# psoc6_01 register map
Vendor: Cypress Semiconductor; Series: psoc6_01; File version: 1.0
CPU: CM4 r0p1, little endian, MPU, FPU, VTOR, 3 interrupt priority bits
Registers are 32-bit, read-write, reset 0x0 unless marked. A register's access mark holds for its fields unless they carry their own. Offsets are from the block's base; [hi:lo] are bit positions; lines under a group give offsets from that group; 'fields as' and 'values as' point back to an identical list.

## USBFS0 (part 2 of 2) — USB Host and Device Controller
Base 0x403F0000
0x4000 USBHOST group — USB Host Controller
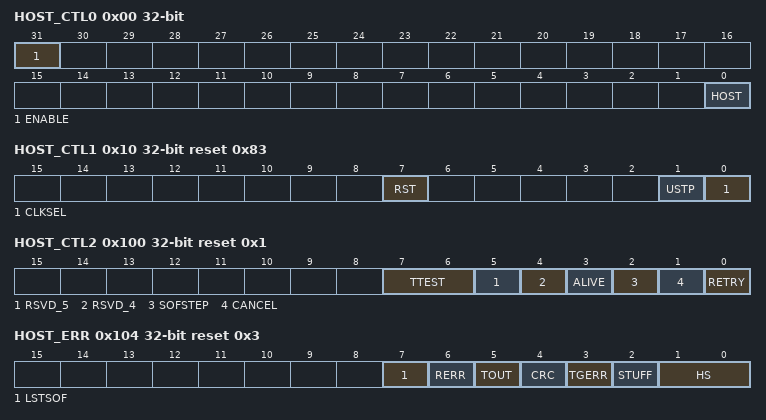
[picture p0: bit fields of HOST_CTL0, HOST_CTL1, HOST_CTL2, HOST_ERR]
  0x00 HOST_CTL0 — Host Control 0 Register.
    [31] ENABLE — This bit enables the operation of this IP. '0' : Disable USB Host '1' : Enable USB Host Note: - This bit doesn' affect the USB Device.
    [0] HOST — This bit selects an operating mode of this IP. '0' : USB Device '1' : USB Host Notes: - The operation mode does not transition to the required one immediately after it was changed using this bit. Read this bit to check that the operation mode has changed. - This bit is initialized if ENABLE bit of the Host Control 0 Register (HOST_CTL0) changes from '1' to '0'.. - Before changing from the USB Host to the USB Device, check that the following conditions are satisfied and also set the RST bit of the Host Control 1 Register (HOST_CTL1). to '1'. * The SOFBUSY bit of the Host Status Register (HOST_STATUS) is set to '0'. * The TKNEN bits of the Host Token Endpoint Register (HOST_TOKEN) is set to '000'. * The SUSP bit of the Host Status Register (HOST_STATUS) is set to '0'.
  0x10 HOST_CTL1 reset 0x83 — Host Control 1 Register.
    [7] RST — This bit resets this IP. '0' : Releases the reset for USB Host. '1' : Resets USB Host. Notes: - This bit is initialized if ENABLE bit of the Host Control 0 Register changes from '1' to '0'. - If this bit is set to '1', both the BFINI bits of the Host Endpoint 1 Control Register (HOST_EP1_CTL) and Host Endpoint 2 Control Register (HOST_EP2_CTL) are set to '1'.
    [1] USTP — This bit stops the clock for the USB Host operating unit. When this bit is '1', power consumption can be reduced by configuring this bit. '0' : Normal mode. '1' : Stops the clock for the USB Host operating unit. Notes: - If this bit is set to '1', the function of USB Host can't be used because internal clock is stopped. - This bit is initialized if ENABLE bit of the Host Control 0 Register (HOST_CTL0) changes from '1' to '0'.
    [0] CLKSEL — This bit selects the operating clock of USB Host. '0' : Low-speed clock '1' : Full-speed clock Notes: - This bit is initialized if ENABLE bit of the Host Control 0 Register (HOST_CTL0) changes from '1' to '0'. - This bit must always be set to '1' in the USB Device mode.
  0x100 HOST_CTL2 reset 0x1 — Host Control 2 Register.
    [7:6] TTEST — Timer Test. Set this bits to '00'.
    [5] RSVD_5
    [4] RSVD_4
    [3] ALIVE — This bit is used to specify the keep-alive function in the low-speed mode. If this bit it set to '1' while the CLKSEL bit of the Host Control 1 Register (HOST_CTL1) is '0', SE0 is output instead of SOF. This bit is effective when the CLKSEL bit of the Host Conrtol 1 Register (HOST_CTL1) is '0'. If the CLKSEL bit is '1', SOF is output regardless of the setting of the ALIVE bit. '0' : SOF output. '1' : SE0 output (Keep alive)
    [2] SOFSTEP — If this bit is set to '1', the SOF interrupt flag (INTR_USBHOST.SOFIRQ) is set to '1' each time SOF is sent. If this bit is set to '0', the set value of the Host SOF Interrupt Frame Compare Register (HOST_FCOMP) is compared with the low-order eight bits of the SOF frame number. If they match, the SOF interrupt flag (INTR_USBHOST.SOFIRQ) is set to '1'. '0' : An interrupt occurred due to the HOST_HFCOMP setting. '1' : An interrupt occurred. Notes: - If a SOF token (TKNEN='001') is sent by the setting of the Host Token Endpoint Register (HOST_TOKEN), the SOF interrupt flag (INTR_USBHOST.SOFIRQ) is not set to '1' regardless of the setting of this bit.
    [1] CANCEL — When this bit is set to '1', if the target token is written to the Host Token Endpoint Register (HOST_TOKEN) in the EOF area (specified in the Host EOF Setup Register), its sending is canceled. When this bit is set to '0', token sending is not canceled even if the target token is written to the register. The cancellation of token sending is detected by reading the TCAN bit of the Interrupt USB Host Register (INTR_USBHOST). '0' : Continues a token. '1' : Cancels a token.
    [0] RETRY — If this bit is set to '1', the target token is retried if a NAK or error* occurs. Retry processing is performed during the time that is specified in the Host Retry Timer Setup Register (HOST_RTIMER). * : HOST_ERR.RERR='1', HOST_ERR.TOUT='1', HOST_ERR.CRC='1', HOST_ERR.TGERR='1', HOST_ERR.STUFF='1' '0' : Doesn't retry token sending. '1' : Retries token sending Note: - This bit isn't initialized even if the RST bit of the Host Control 1 Register (HOST_CTL1) is set to '1'.
  0x104 HOST_ERR reset 0x3 — Host Error Status Register.
    [7] LSTSOF — If this bit is set to '1', it means that the SOF token can't be sent in the USB Host because other token is in process. When this bit is '0', it means that no lost SOF error is detected. If this bit is written with '1', it is set to '0'. However, if this bit is written with '0', its value is ignored. '0' : Sends SOF. '1' : SOF sending error. Note: - This bit is set to the initial value when the RST bit of the Host Control 1 Register (HOST_CTL1) is set to '1'.
    [6] RERR — When this bit is set to '1', it means that the received data exceeds the specified maximum number of packets in the USB Host. If a receive error is detected, bit5 (Timeout) of this register is also set to '1'. When this bit is '0', it means that no error occurs. If this bit is written with '1', it is set to '0'. However, if this bit is written with '0', its value is ignored. '0' : No receive error. '1' : Maximum packet receive error. - This bit is set to the initial value when the RST bit of the Host Control 1 Register (HOST_CTL1) is set to '1'.
    [5] TOUT — If this bit is set to '1', it means that no response is returned from the device within the specified time after a token has been sent in the USB Host. When this bit is '0', it means that no timeout is detected. When this bit is '0', it means that no error occurs. If this bit is written with '1', it is set to '0'. However, if this bit is written with '0', its value is ignored. '0' : No timeout. '1' : Timeout occurs. Note: - This bit is set to the initial value when the RST bit of the Host Control 1 Register (HOST_CTL1) is set to '1'.
    [4] CRC — If this bit is set to '1', it means that a CRC error is detected in the USB Host. When this bit is '0', it means that no CRC error is detected. If a CRC error is detected, bit5 (Timeout) of this register is also set to '1'. When this bit is '0', it means that no CRC error is detected. If this bit is written with '1', it is set to '0'. However, if this bit is written with '0', its value is ignored. '0' : No CRC error. '1' : CRC error occurs. Note: - This bit is set to the initial value when the RST bit of the Host Control 1 Register (HOST_CTL1) is set to '1'.
    [3] TGERR — If this bit is set to '1', it means that the data of this bit does not match the value of the received toggle data. When this bit is '0', it means that no toggle error is detected. If this bit is written with '1', it is set to '0'. However, if this bit is written with '0', its value is ignored. '0' : No toggle error. '1' : Toggle error occurs. Note: - This bit is set to the initial value when the RST bit of the Host Control 1 Register (HOST_CTL1) is set to '1'.
    [2] STUFF — If this bit is set to '1', it means that a bit stuffing error is detected. When this bit is '0', it means that no stuffing error is detected. If a stuffing error is detected, bit5 (Timeout) of this register is also set to '1'. If this bit is written with '1', it is set to '0'. However, if this bit is written with '0', its value is ignored. '0' : No stuffing error. '1' : Stuffing error occurs. Note: - This bit is set to the initial value when the RST bit of the Host Control 1 Register (HOST_CTL1) is set to '1'.
    [1:0] HS — These flags indicate the status of a handshake packet to be sent or received. These flags are set to 'NULL' when no handshake occurs due to an error or when a SOF token has been ended with the TKNEN bit of the Host Token Endpoint Register (HOST_TOKEN). These bits are updated when sending or receiving has been ended. HS bits change values '11' under the following condition. However, if HS bits are written except the following conditions, the values are ignored. - HS bits indicate values except '11' and write the value '11' to HS bits. Note: This bit is set to the initial value when the RST bit of the Host Control 1 Register (HOST_CTL1) is set to '1'.
      0=ACK (Acknowledge Packet); 1=NAK (Non-Acknowledge Packet); 2=STALL (Stall Packet); 3=NULL (Null Packet)
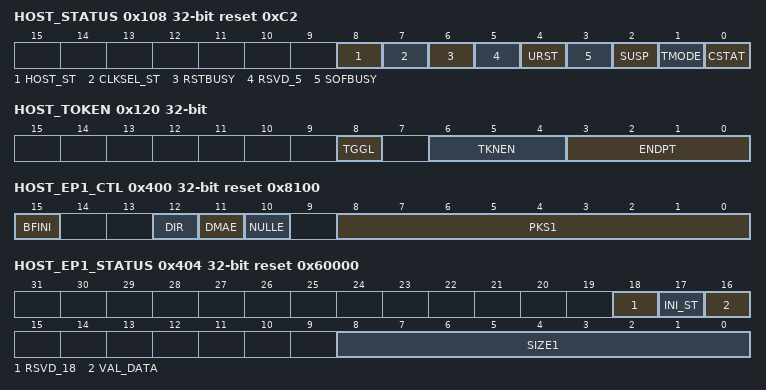
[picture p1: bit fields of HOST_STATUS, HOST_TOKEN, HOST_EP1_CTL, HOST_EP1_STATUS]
  0x108 HOST_STATUS reset 0xC2
    [8] HOST_ST ro — This bit shows whether it is USB Host mode. If the HOST bit of the Host Control Register (HOST_CTL0) is set to '1', this bit is set to '1'. '0' : USB Device '1' : USB Host Notes: - If this bit is different from the CLKSEL bit, The execution of the token must be waited until the match. - This bit takes time to be initialized by the RST bit of the Host Control 1 Resgiter (HOST_CTL1).
    [7] CLKSEL_ST ro — This bit shows whether it is full-speed or not. If the CLKSEL bit of the Host Control 1 Register (HOST_CTL1) is set to '1', this bit is set to '1'. '0' : Low speed '1' : Full speed Note: - If this bit is different from the CLKSEL bit, The execution of the token and bus reset must be waited until the match. - This bit takes time to be initialized by the RST bit of the Host Control 1 Resgiter (HOST_CTL1).
    [6] RSTBUSY ro — This bit shows that USB Host is being reset internally. If the RST bit of the Host Control 1 Register (HOST_CTL1) is set to '1', this bit is set to '1'. If the RST bit of Host Control 1 Register (HOST_CTL1) is set to '0', this bit is set to '0'. '0' : USB Host isn't being reset. '1' : USB Host is being reset. Notes: - If this bit is '1', the token must't be executed. - This bit isn't set to '0' or '1' immediately evne if the RST bit of Host Control 1 Register (HOST_CTL1) is set to '0' or '1'.
    [5] RSVD_5 ro
    [4] URST — When this bit is set to '1', the USB bus is reset. This bit continues set to '1' during USB bus resetting, and changes to '0' when USB bus resetting is ended. If this bit is set to '0', no processing is performed.
    [3] SOFBUSY — When a SOF token is sent using the Host Token Endpoint Register (HOST_TOKEN), this bit is set to '1', which means that the SOF timer is active. When this bit is '0', it means that the SOF timer is under suspension. To stop the active SOF timer, write '0' to this bit. However, if this bit is written with '1', its value is ignored. '0' : The SOF timer is stopped. '1' : The SOF timer is active. Notes: - This bit is set to the initial value when the RST bit of the Host Control 1 Register (HOST_CTL1) is set to '1'. - This bit takes time to be initialized by the RST bit of the Host Control 1 Resgiter (HOST_CTL1). - The SOF timer does not stop immediately after this bit has been set to '0' to stop the SOF timer. To check whether or not the SOF timer is stopped, read this bit.
    [2] SUSP — If this bit is set to '1', the USB Host is placed into the suspend state. If this bit is set to '0' while it is '1' or the USB bus is placed into the k-state mode, the suspend state is released, and the RWIRQ bit of the Interrupt USB Host Register (INTR_USBHOST) is set to '1'. Set to '1' : Suspend. Set '0' while this bit is '1' : Resume. Others : Holds the status. Notes: - This bit is set to the initial value when the RST bit of the Host Control 1 Register (HOST_CTL1) is set to '1'. - This bit takes time to be initialized by the RST bit of the Host Control 1 Resgiter (HOST_CTL1). - If this bit is set to '1', this bit must not be set to '1' until the RWIRQ bit of the Interrupt USB Host Register (INTR_USBHOST) is set to '1'. - Do not set this bit to '1' while the USB is active (during USB bus resetting, data transfer, or SOF timer running). - If the value of this bit is changed, it is not immediately reflected on the state of the USB bus. To check whether or not the state is updated, read this bit.
    [1] TMODE ro — If this bit is '1', it means that the device is connected in the full-speed mode. When this bit is '0', it means that the device is connected in the low-speed mode. This bit is valid when the CSTAT bit of the Host Status Register (HOST_STATUS) is '1'. '0' : Low-speed. '1' : Full-speed. Notes: - This bit is initialized if the RST bit of the Host Control 1 Register (HOST_CTL1) is set to '1'. - This bit takes time to be initialized by the RST bit of the Host Control 1 Resgiter (HOST_CTL1).
    [0] CSTAT ro — When this bit is '1', it means that the device is connected. When this bit is '0', it means that the device is disconnected. '0' : Device is disconnected. '1' : Device is connected. Notes: - This bit is initialized if the RST bit of the Host Control 1 Register (Host_CTL1) is set to '1'. - This bit takes time to be initialized by the RST bit of the Host Control 1 Resgiter (HOST_CTL1).
  0x10C HOST_FCOMP — Host SOF Interrupt Frame Compare Register
    [7:0] FRAMECOMP — These bits are used to specify the data to be compared with the low-order eight bits of a frame number when sending a SOF token. If the SOFSTEP bit of Host Control 2 Register (HOST_CTL2) is '0', the frame number of SOF is compared with the value of this register when sending a SOF token. If they match, the SOFIRQ bit of the Interrupt USB Host Register (INTR_USBHOST) is set to '1'. The setting of this register is invalid when the SOFSTEP bit of Host Control 2 Register (HOST_CTL2) is '1'. Note: - This bit is not initialized even if the RST bit of the Host Control 1 Register (HOST_CTL1) is set to '1'.
  0x110 HOST_RTIMER — Host Retry Timer Setup Register
    [17:0] RTIMER — These bits are used to specify the retry time in this register. The retry timer is activated when token sending starts while the RETRY bit of Host Control 2 Register (HOST_CTL2) is '1'. The retry time is then decremented by one when a 1-bit transfer clock (12 MHz in the full-speed mode) is output. When the retry timer reaches 0, the target token is sent, and processing is ended. If a token retry occurs in the EOF area, the retry timer is stopped until SOF sending is ended. After SOF sending has been completed, the retry timer restarts with the value that is set when the timer stopped.
  0x114 HOST_ADDR — Host Address Register
    [6:0] ADDRESS — These bits are used to specify a token address. Note: - This bit is not initialized even if the RST bit of the Host Control 1 Register (HOST_CTL1) is set to '1'.
  0x118 HOST_EOF — Host EOF Setup Register
    [13:0] EOF — These bits are used to specify the time to disable token sending before transferring SOF. Specify the time with a margin, which is longer than the one-packet length. The time unit is the 1-bit transfer time. Setting example: MAXPKT = 64 bytes, full-speed mode (Token_length + packet_length + header + CRC)*7/6 + Turn_around_time =(34 bit + 546 bit)*7/6 + 36 bit = 712.7 bit Therefore, set 0x2C9. Note: - This bit is not initialized even if the RST bit of the Host Control 1 Register (HOST_CTL1) is set to '1'.
  0x11C HOST_FRAME — Host Frame Setup Register
    [10:0] FRAME — These bits are used to specify a frame number of SOF. Notes: - This bit isn't initialized even if the RST bit of the Host Control 1 Register (HOST_CTL1) is set to '1'. - Specify a frame number in this register before setting SOF in the TKNEN bit of the Host Token Endpoint Register (HOST_TOKEN). - This register cannot be written while the SOFBUSY bit of the Host Status Register (HOST_STATUS) is '1' and a SOF token is in process.
  0x120 HOST_TOKEN — Host Token Endpoint Register
    [8] TGGL — This bit is used to set toggle data. Toggle data is sent depending on the setting of this bit. When receiving toggle data, received toggle data is compared with the toggle data of this bit to verify whether or not an error occurs. '0' : DATA0 '1' : DATA1 Notes: - This bit isn't initialized even if the RST bit of the Host Control 1 Register (HOST_CTL1) is set to '1'. - Set this bit when the TKNEN bit of the Host Token Endpoint Register (HOST_TOKEN) is '000'.
    [6:4] TKNEN — These bits send a token according to the settings. After operation has been ended, the TKNEN bit is set to '000', and the CMPIRQ bit of the Interrupt USB Host Register (INTR_USBHOST) is set to '1'. The settings of the TGGL and ENDPT bits are ignored when sending a SOF token. Notes: - This bit is set to the initial value when the RST bit of the Host Control 1 Register (HOST_CTL1) is set to '1'. - The PRE packet isn't supported. - Do not set '100' to the TKNEN bit when the SOFBUSY bit of the Host Status Register (HOST_STATUS) is '1' - Change the USB to the USB Host before writing data to this bit. - When issuing a token again after the token interrupt flag (CMPIRQ) has been set to '1', wait for 3 cycles or more after a USB transfer clock (12 MHz in the full-speed mode, 1.5 MHz in the low-speed mode) was output, then write data to this bit. - Read the value of TKNEN bit if a new value is written in it .Continue writing in this bit until a retrieved value equals a new value written in. During this checking process, it is needed to prevent any interrupt. - Take the following steps when CMPIRQ bit of Interrupt USB Host Register (INTR_USBHOST) is set to '1' by finishing IN token or Isochronous IN token. 1. Read HS bit of Host Error Status Register (HOST_ERR), then set CMPIRQ bit to '0'. 2. Set EPn bit of Host DMA Enable Register (HOST_DMA_ENBL) (n=1 or 2) to '1' if HS bit of Host Error Status Register (HOST_ERR) is equal to '00' and wait until EPn bit of Host DMA Data Request Register (HOST_DMA_DREQ) changes to '1'. Finish the IN token processing if HS bit is not equal to '00'. 3. Read the received data if EPn bit of Host DMA Data Requet (HOST_DMA_DREQ) (n=1 or 2) changes to '1'.
      0=NONE (Sends no data.); 1=SETUP (Sends SETUP token.); 2=IN (Sends IN token.); 3=OUT (Sends OUT token.); 4=SOF (Sends SOF token.); 5=ISO_IN (Sends Isochronous IN.); 6=ISO_OUT (Sends Isochronous OUT.); 7=RSV (N/A)
    [3:0] ENDPT — These bits are used to specify an endpoint to send or receive data to or from the device. Note: - This bit isn't initialized even if the RST bit of the Host Control 1 Register (HOST_CTL1) is set to '1'.
  0x400 HOST_EP1_CTL reset 0x8100 — Host Endpoint 1 Control Register
    [15] BFINI — This bit initializes the send/receive buffer of transfer data. The BFINI bit is also automatically set by setting the RST bit of the HOST Control 1 Register (HOST_CTL1). If the RST bit was used for resetting, therefore, set the RST bit to '0' before clearing the BFINI bit. '0' : Clears the initialization. '1' : Initializes the send/receive buffer Note : - The EP1 buffer has a double-buffer configuration. The BFINI bit initialization initializes the double buffers concurrently and also initializes the EP1DRQ and EP1SPK bits.
    [12] DIR — This bit specifies the transfer direction the Endpoint support. '0' : IN Endpoint. '1' : OUT Endpoint Note: - This bit must be changed when INI_ST bit of the Host Endpoint 1 Status Register (HOST_EP1_STATUS) is '1'.
    [11] DMAE — This bit sets a mode that uses DMA for writing or reading transfer data to/from send/receive buffer, and automatically transfers the send/receive data synchronized with an data request in the IN or OUT direction. Until the data size set in the DMA is reached, the data is transferred. '0' : Releases the automatic buffer transfer mode. '1' : Sets the automatic buffer transfer mode. Note : - The CPU must not access the send/receive buffer while the DMAE bit is set to '1'. For data transfer in the IN direction, set the DMA transfer size to the multiples of that set in PKS bits of the Host EP1 Control Register (HOST_EP1_CTL) and Host EP2 Control Register (HOST_EP2_CTR).
    [10] NULLE — When a data transfer request in OUT the direction is transmitted while automatic buffer transfer mode is set (DMAE = 1), this bit sets a mode that transfers 0-byte data automatically upon the detection of the last packet transfer. '0' : Releases the NULL automatic transfer mode. '1' : Sets the NULL automatic transfer mode. Note : - For data transfer in the IN direction or when automatic buffer transfer mode is not set, the NULL bit configuration does not affect communication.
    [8:0] PKS1 — This bit specifies the maximum size transferred by one packet. The configurable range is from 0x001 to 0x100. - If automatic buffer transfer mode (DMEA='1') is used, this Endpoint must not set from 0 to 2.
  0x404 HOST_EP1_STATUS ro reset 0x60000 (reset mask 0x70000) — Host Endpoint 1 Status Register
    [18] RSVD_18
    [17] INI_ST — This bit shows that EP1 is initialized. If the init bit of the Host Endpoint 1 Control Register (HOST_EP1_CTL) is set to '1' and EP1 is initialized, this bit is to '1'. '0' : Release of the initialization '1' : Initialization Note: - This bit isn't set to '0' or '1' immediately evne if BFINI bit of the Host Endpoint 1 Control Register (HOST_EP1_CTL) is set to '0' or '1'.
    [16] VAL_DATA — This bit shows that there is valid data in the EP1 buffer. '0' : Invalid data in the buffer '1' : Valid data in the buffer
    [8:0] SIZE1 — These bits indicate the number of data bytes written to the receive buffer when IN packet transfer of EP1 has finished. The indication range is from 0x000 to 0x100. Note : - These bits are set to the data size transferred in the IN direction and written to the buffer. Therefore, a value read during transfer in the OUT direction has no effect.
  0x408 HOST_EP1_RW1_DR — Host Endpoint 1 Data 1-Byte Register
    [7:0] BFDT8 — Data Register for EP1. The 1-Byte data is valid.
  0x40C HOST_EP1_RW2_DR — Host Endpoint 1 Data 2-Byte Register
    [15:0] BFDT16 — Data Register for EP1. The 2-Byte data is valid.
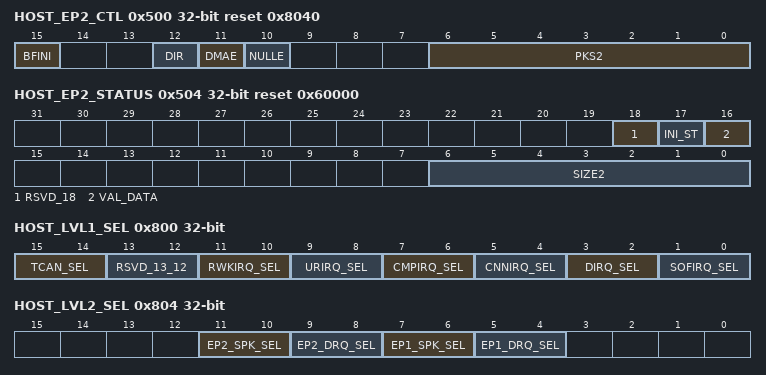
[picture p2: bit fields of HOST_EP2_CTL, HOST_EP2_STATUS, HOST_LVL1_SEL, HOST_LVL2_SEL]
  0x500 HOST_EP2_CTL reset 0x8040 — Host Endpoint 2 Control Register
    [15] BFINI — This bit initializes the send/receive buffer of transfer data. The BFINI bit is also automatically set by setting the RST bit of the HOST Control 1 Register (HOST_CTL1). If the RST bit was used for resetting, therefore, set the RST bit to '0' before clearing the BFINI bit. '0' : Clears the initialization. '1' : Initializes the send/receive buffer Note : - The EP2 buffer has a double-buffer configuration. The BFINI bit initialization initializes the double buffers concurrently and also initializes the EP2DRQ and EP2SPK bits.
    [12] DIR — This bit specifies the transfer direction the Endpoint support. '0' : IN Endpoint. '1' : OUT Endpoint Note: - This bit must be changed when INI_ST bit of the Host Endpoint 2 Status Register (HOST_EP2_STATUS) is '1'.
    [11] DMAE — This bit sets a mode that uses DMA for writing or reading transfer data to/from send/receive buffer, and automatically transfers the send/receive data synchronized with an data request in the IN or OUT direction. Until the data size set in the DMA is reached, the data is transferred. '0' : Releases the automatic buffer transfer mode. '1' : Sets the automatic buffer transfer mode. Note : - The CPU must not access the send/receive buffer while the DMAE bit is set to '1'. For data transfer in the IN direction, set the DMA transfer size to the multiples of that set in PKS bits of the Host EP1 Control Register (HOST_EP1_CTL) and Host EP2 Control Register (HOST_EP2_CTR).
    [10] NULLE — When a data transfer request in OUT the direction is transmitted while automatic buffer transfer mode is set (DMAE = 1), this bit sets a mode that transfers 0-byte data automatically upon the detection of the last packet transfer. '0' : Releases the NULL automatic transfer mode. '1' : Sets the NULL automatic transfer mode. Note : - For data transfer in the IN direction or when automatic buffer transfer mode is not set, the NULL bit configuration does not affect communication.
    [6:0] PKS2 — This bit specifies the maximum size transferred by one packet. The configurable range is from 0x001 to 0x40. - If automatic buffer transfer mode (DMEA='1') is used, this Endpoint must not set from 0 to 2.
  0x504 HOST_EP2_STATUS ro reset 0x60000 (reset mask 0x70000) — Host Endpoint 2 Status Register
    [18] RSVD_18
    [17] INI_ST — This bit shows that EP2 is initialized. If the BFINI bit of the Host Endpoint 2 Control Register (HOST_EP2_CTL) is set to '1' and EP2 is initialized, this bit is to '1'. '0' : Release of the initialization '1' : Initialization Note: - This bit isn't set to '0' or '1' immediately evne if BFINI bit of the Host Endpoint 2 Control Register (HOST_EP2_CTL) is set to '0' or '1'.
    [16] VAL_DATA — This bit shows that there is valid data in the EP2 buffer. '0' : Invalid data in the buffer '1' : Valid data in the buffer
    [6:0] SIZE2 — These bits indicate the number of data bytes written to the receive buffer when IN packet transfer of EP2 has finished. The indication range is from 0x000 to 0x40. Note : - These bits are set to the data size transferred in the IN direction and written to the buffer. Therefore, a value read during transfer in the OUT direction has no effect.
  0x508 HOST_EP2_RW1_DR — Host Endpoint 2 Data 1-Byte Register
    [7:0] BFDT8 — Data Register for EP2. The 1-Byte data is valid.
  0x50C HOST_EP2_RW2_DR — Host Endpoint 2 Data 2-Byte Register
    [15:0] BFDT16 — Data Register for EP2. The 2-Byte data is valid.
  0x800 HOST_LVL1_SEL — Host Interrupt Level 1 Selection Register
    [15:14] TCAN_SEL — These bits assign TCAN interrupt flag to any interrupt signals.
    [13:12] RSVD_13_12
    [11:10] RWKIRQ_SEL — These bits assign RWKIRQ interrupt flag to any interrupt signals.
    [9:8] URIRQ_SEL — These bits assign URIRQ interrupt flag to any interrupt signals.
    [7:6] CMPIRQ_SEL — These bits assign URIRQ interrupt flag to any interrupt signals.
    [5:4] CNNIRQ_SEL — These bits assign CNNIRQ interrupt flag to any interrupt signals.
    [3:2] DIRQ_SEL — These bits assign DIRQ interrupt flag to any interrupt signals.
    [1:0] SOFIRQ_SEL — These bits assign SOFIRQ interrupt flag to any interrupt signals.
      0=HI (High priority interrupt); 1=MED (Medium priority interrupt); 2=LO (Low priority interrupt); 3=RSVD (illegal)
  0x804 HOST_LVL2_SEL — Host Interrupt Level 2 Selection Register
    [11:10] EP2_SPK_SEL — These bits assign EP2_SPK interrupt flag to any interrupt signals.
    [9:8] EP2_DRQ_SEL — These bits assign EP2_DRQ interrupt flag to any interrupt signals.
    [7:6] EP1_SPK_SEL — These bits assign EP1_SPK interrupt flag to any interrupt signals.
    [5:4] EP1_DRQ_SEL — These bits assign EP1_DRQ interrupt flag to any interrupt signals.
      values as USBHOST.HOST_LVL1_SEL.SOFIRQ_SEL
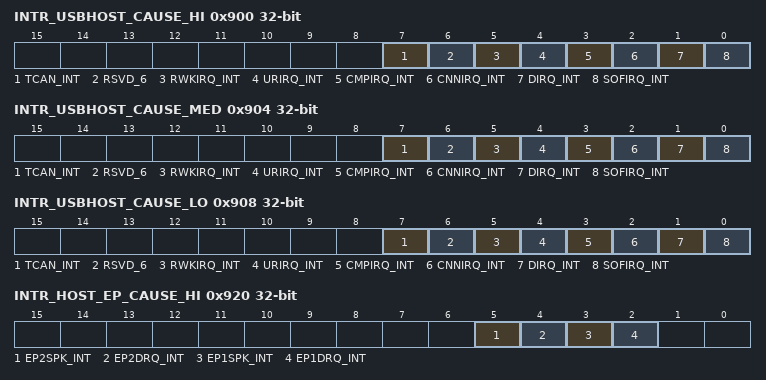
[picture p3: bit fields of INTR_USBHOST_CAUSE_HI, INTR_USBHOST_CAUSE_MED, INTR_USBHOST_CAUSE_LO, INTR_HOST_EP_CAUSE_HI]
  0x900 INTR_USBHOST_CAUSE_HI ro — Interrupt USB Host Cause High Register
    [7] TCAN_INT — TCAN interrupt
    [6] RSVD_6
    [5] RWKIRQ_INT — RWKIRQ interrupt
    [4] URIRQ_INT — URIRQ interrupt
    [3] CMPIRQ_INT — CMPIRQ interrupt
    [2] CNNIRQ_INT — CNNIRQ interrupt
    [1] DIRQ_INT — DIRQ interrupt
    [0] SOFIRQ_INT — SOFIRQ interrupt
  0x904 INTR_USBHOST_CAUSE_MED ro — Interrupt USB Host Cause Medium Register
    fields as USBHOST.INTR_USBHOST_CAUSE_HI
  0x908 INTR_USBHOST_CAUSE_LO ro — Interrupt USB Host Cause Low Register
    fields as USBHOST.INTR_USBHOST_CAUSE_HI
  0x920 INTR_HOST_EP_CAUSE_HI ro — Interrupt USB Host Endpoint Cause High Register
    [5] EP2SPK_INT — EP2SPK interrupt
    [4] EP2DRQ_INT — EP2DRQ interrupt
    [3] EP1SPK_INT — EP1SPK interrupt
    [2] EP1DRQ_INT — EP1DRQ interrupt
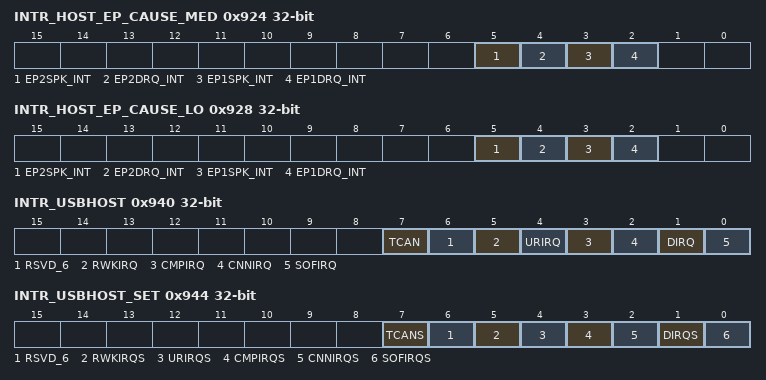
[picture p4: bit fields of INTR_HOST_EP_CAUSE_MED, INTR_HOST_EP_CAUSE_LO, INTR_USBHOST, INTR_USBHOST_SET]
  0x924 INTR_HOST_EP_CAUSE_MED ro — Interrupt USB Host Endpoint Cause Medium Register
    fields as USBHOST.INTR_HOST_EP_CAUSE_HI
  0x928 INTR_HOST_EP_CAUSE_LO ro — Interrupt USB Host Endpoint Cause Low Register
    fields as USBHOST.INTR_HOST_EP_CAUSE_HI
  0x940 INTR_USBHOST — Interrupt USB Host Register
    [7] TCAN — If this bit is set to '1', it means that token sending is canceled based on the setting of the CANCEL bit of Host Control 2 Register (HOST_CTL2). When this bit is '0', it means that token sending is not canceled. If this bit is written with '1', it is set to '0'. However, if this bit is written with '0', its value is ignored. '0' : Does not cancel token sending. '1' : Cancels token sending. Note : - This bit is set to the initial value when the RST bit of the Host Control 1 Register (HOST_CTL1) is set to '1'.
    [6] RSVD_6
    [5] RWKIRQ — If this bit is set to '1', it means that remote Wake-up is ended. When this bit is '0', it has no meaning. If this bit is written with '1', it is set to '0'. However, if this bit is written with '0', its value is ignored. '0' : Issues no interrupt request by restart. '1' : Issues an interrupt request by restart. Note : - This bit is set to the initial value when the RST bit of the Host Control 1 Register (HOST_CTL1) is set to '1'.
    [4] URIRQ — If this bit is set to '1', it means that USB bus resetting is ended. When this bit is '0', it has no meaning. If this bit is written with '1', it is set to '0'. However, if this bit is written with '0', its value is ignored. '0' : Issues no interrupt request by USB bus resetting. '1' : Issues an interrupt request by USB bus resetting. Note : - This bit is set to the initial value when the RST bit of the Host Control 1 Register (HOST_CTL1) is set to '1'.
    [3] CMPIRQ — If this bit is set to '1', it means that a token is completed. When this bit is '0', it has no meaning. If this bit is written with '1', it is set to '0'. However, if this bit is written with '0', its value is ignored. '0' : Issues no interrupt request by token completion. '1' : Issues an interrupt request by token completion. Note : - This bit is set to the initial value when the RST bit of the Host Control 1 Register (HOST_CTL1) is set to '1'. - This bit is not set to '1' even if the TCAN bit of the Interrupt USBHost Register (INTR_USBHOST) changes to '1'. - Take the following steps when this bit is set to '1' by finishing IN token or Isochronous IN token. 1. Read HS bit of Host Error Status Register (HOST_ERR), then set CMPIRQ bit to '0'. 2. Set EPn bit of Host DMA Enable Register (HOST_DMA_ENBL) (n=1 or 2) to '1' if HS bit of Host Error Status Register (HOST_ERR) is equal to '00' and wait until EPn bit of Host DMA Data Request Register (HOST_DMA_DREQ) changes to '1'. Finish the IN token processing if HS bit is not equal to '00'. 3. Read the received data if EPn bit of Host DMA Data Requet (HOST_DMA_DREQ) (n=1 or 2) changes to '1'.
    [2] CNNIRQ — If this bit is set to '1', it means that a device connection is detected. When this bit is '0', it has no meaning. If this bit is written with '1', it is set to '0'. However, if this bit is written with '0', its value is ignored. '0' : Issues no interrupt request by detecting a device connection. '1' : Issues an interrupt request by detecting a device connection. Note : - This bit is set to the initial value when the RST bit of the Host Control 1 Register (HOST_CTL1) is set to '1'.
    [1] DIRQ — If this bit is set to '1', it means that a device disconnection is detected. When this bit is '0', it has no meaning. If this bit is written with '1', it is set to '0'. However, if this bit is written with '0', its value is ignored. '0' : Issues no interrupt request by detecting a device disconnection. '1' : Issues an interrupt request by detecting a device disconnection. Note : - This bit is set to the initial value when the RST bit of the Host Control 1 Register (HOST_CTL1) is set to '1'.
    [0] SOFIRQ — If this bit is set to '1', it means that SOF token sending is started. When this bit is '0', it has no meaning. If this bit is written with '1', it is set to '0'. However, if this bit is written with '0', its value is ignored. '0' : Does not issue an interrupt request by starting a SOF token. '1' : Issues an interrupt request by starting a SOF token. Note : - This bit is set to the initial value when the RST bit of the Host Control 1 Register (HOST_CTL1) is set to '1'.
  0x944 INTR_USBHOST_SET — Interrupt USB Host Set Register
    [7] TCANS — This bit sets TCAN bit. If this bit is written to '1', TCAN is set to '1'. However, if this bit is written with '0', its value is ignored.
    [6] RSVD_6 — BCNFTEST interrupt. This bit is test bit
    [5] RWKIRQS — This bit sets RWKIRQ bit. If this bit is written to '1', RWKIRQ is set to '1'. However, if this bit is written with '0', its value is ignored.
    [4] URIRQS — This bit sets URIRQ bit. If this bit is written to '1', URIRQ is set to '1'. However, if this bit is written with '0', its value is ignored.
    [3] CMPIRQS — This bit sets CMPIRQ bit. If this bit is written to '1', CMPIRQ is set to '1'. However, if this bit is written with '0', its value is ignored.
    [2] CNNIRQS — This bit sets CNNIRQ bit. If this bit is written to '1', CNNIRQ is set to '1'. However, if this bit is written with '0', its value is ignored.
    [1] DIRQS — This bit sets DIRQ bit. If this bit is written to '1', DIRQ is set to '1'. However, if this bit is written with '0', its value is ignored.
    [0] SOFIRQS — This bit sets SOFIRQ bit. If this bit is written to '1', SOFIRQ is set to '1'. However, if this bit is written with '0', its value is ignored.
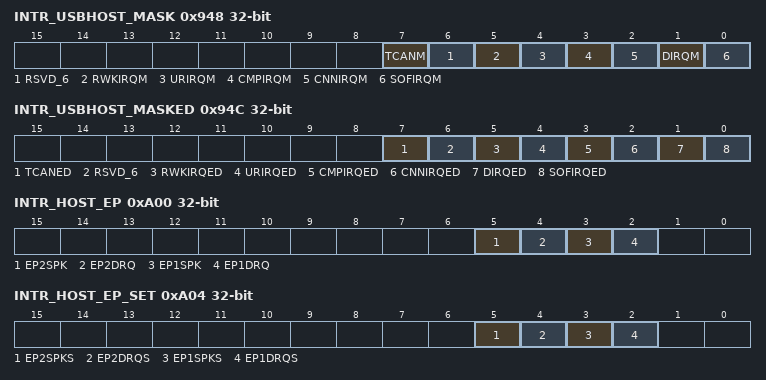
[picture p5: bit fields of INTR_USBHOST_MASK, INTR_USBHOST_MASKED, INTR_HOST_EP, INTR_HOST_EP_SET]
  0x948 INTR_USBHOST_MASK — Interrupt USB Host Mask Register
    [7] TCANM — This bit masks the interrupt by TCAN flag. '0' : Disables '1' : Enables
    [6] RSVD_6
    [5] RWKIRQM — This bit masks the interrupt by RWKIRQ flag. '0' : Disables '1' : Enables
    [4] URIRQM — This bit masks the interrupt by URIRQ flag. '0' : Disables '1' : Enables
    [3] CMPIRQM — This bit masks the interrupt by CMPIRQ flag. '0' : Disables '1' : Enables
    [2] CNNIRQM — This bit masks the interrupt by CNNIRQ flag. '0' : Disables '1' : Enables
    [1] DIRQM — This bit masks the interrupt by DIRQ flag. '0' : Disables '1' : Enables
    [0] SOFIRQM — This bit masks the interrupt by SOF flag. '0' : Disables '1' : Enables
  0x94C INTR_USBHOST_MASKED ro — Interrupt USB Host Masked Register
    [7] TCANED — This bit indicates the interrupt by TCAN flag. '0' : Doesn't request the interrupt by TCAN '1' : Request the interrupt by TCAN
    [6] RSVD_6
    [5] RWKIRQED — This bit indicates the interrupt by RWKIRQ flag. '0' : Doesn't request the interrupt by RWKIRQ '1' : Request the interrupt by RWKIRQ
    [4] URIRQED — This bit indicates the interrupt by URIRQ flag. '0' : Doesn't request the interrupt by URIRQ '1' : Request the interrupt by URIRQ
    [3] CMPIRQED — This bit indicates the interrupt by CMPIRQ flag. '0' : Doesn't request the interrupt by CMPIRQ '1' : Request the interrupt by CMPIRQ
    [2] CNNIRQED — This bit indicates the interrupt by CNNIRQ flag. '0' : Doesn't request the interrupt by CNNIRQ '1' : Request the interrupt by CNNIRQ
    [1] DIRQED — This bit indicates the interrupt by DIRQ flag. '0' : Doesn't request the interrupt by DIRQ '1' : Request the interrupt by DIRQ
    [0] SOFIRQED — This bit indicates the interrupt by SOF flag. '0' : Doesn't request the interrupt by SOF '1' : Request the interrupt by SOF
  0xA00 INTR_HOST_EP — Interrupt USB Host Endpoint Register
    [5] EP2SPK — This bit indicates that the data size transferred from the host does not satisfy the maximum packet size (including 0-byte) set by PKS in the Host Endpoint 2 Control Register (HOST_EP2_CTL) when the data has been received successfully. This bit is an interrupt cause, and writing '0' is ignored. Clear it by writing '1'. '0' : Received data size satisfies the maximum packet size '1' : Received data size does not satisfy the maximum packet size Note : - The SPK bit is not set during data transfer in the OUT direction.
    [4] EP2DRQ — This bit indicates that the EP2 packet transfer has normally ended, and processing of the data is required. The DRQ bit is an interrupt cause, and writing '0' is ignored. Clear the DRQ bit by writing '1'. '0' : Clears the interrupt cause '1' : Packet transfer normally ended Note : - If automatic buffer transfer mode (DMAE = '1') is not used, '1' must be written to the DRQ bit after data has been written or read to/from the send/receive buffer. Switch the access buffers once the DRQ bit is cleared. That DRQ = '0' may not be read after the DRQ bit is cleared. If the transfer direction is set to OUT, and the DRQ bit is cleared without writing buffer data while the DRQ bit is '1', it implies that 0-byte data is set. If DIR of the Host Endpoint 2 Control Register (HOST_EP2_CTL) is set to '1' at initial settings, the DRQ bit of corresponding Endpoint is set at the same time. Also while the DRQ bit is not set, '1' must not be written.
    [3] EP1SPK — This bit indicates that the data size transferred from the host does not satisfy the maximum packet size (including 0-byte) set by PKS in the Host Endpoint 1 Control Register (HOST_EP1_CTL) when the data has been received successfully. This bit is an interrupt cause, and writing '0' is ignored. Clear it by writing '1'. '0' : Received data size satisfies the maximum packet size '1' : Received data size does not satisfy the maximum packet size Note : - The SPK bit is not set during data transfer in the OUT direction.
    [2] EP1DRQ — This bit indicates that the EP1 packet transfer has normally ended, and processing of the data is required. The DRQ bit is an interrupt cause, and writing '0' is ignored. Clear the DRQ bit by writing '1'. '0' : Clears the interrupt cause '1' : Packet transfer normally ended Note : - If automatic buffer transfer mode (DMAE = '1') is not used, '1' must be written to the DRQ bit after data has been written or read to/from the send/receive buffer. Switch the access buffers once the DRQ bit is cleared. That DRQ = '0' may not be read after the DRQ bit is cleared. If the transfer direction is set to OUT, and the DRQ bit is cleared without writing buffer data while the DRQ bit is '1', it implies that 0-byte data is set. If DIR of the Host Endpoint 1 Control Register (HOST_EP1_CTL) is set to '1' at initial settings, the DRQ bit of corresponding Endpoint is set at the same time. Also while the DRQ bit is not set, '1' must not be written.
  0xA04 INTR_HOST_EP_SET — Interrupt USB Host Endpoint Set Register
    [5] EP2SPKS — This bit sets EP2SPK bit. If this bit is written to '1', EP2SPK is set to '1'. However, if this bit is written with '0', its value is ignored. Note: If BFINI bit of the Host Endpoint 2 Control Register (HOST_EP2_CTL) is '1', EP2SPK can't be set to '1'.
    [4] EP2DRQS — This bit sets EP2DRQ bit. If this bit is written to '1', EP2DRQ is set to '1'. However, if this bit is written with '0', its value is ignored. Note: If BFINI bit of the Host Endpoint 2 Control Register (HOST_EP2_CTL) is '1', EP2DRQ can't be set to '1'.
    [3] EP1SPKS — This bit sets EP1SPK bit. If this bit is written to '1', EP1SPK is set to '1'. However, if this bit is written with '0', its value is ignored. Note: If BFINI bit of the Host Endpoint 1 Control Register (HOST_EP1_CTL) is '1', EP1SPK can't be set to '1'.
    [2] EP1DRQS — This bit sets EP1DRQ bit. If this bit is written to '1', EP1DRQ is set to '1'. However, if this bit is written with '0', its value is ignored. Note: If BFINI bit of the Host Endpoint 1 Control Register (HOST_EP1_CTL) is '1', EP1DRQ can't be set to '1'.
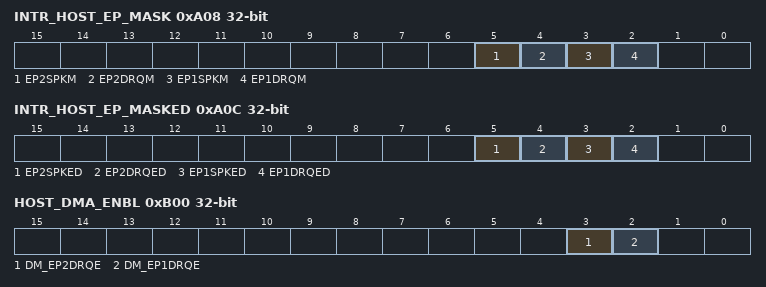
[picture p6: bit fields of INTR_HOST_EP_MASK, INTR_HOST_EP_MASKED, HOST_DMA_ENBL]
  0xA08 INTR_HOST_EP_MASK — Interrupt USB Host Endpoint Mask Register
    [5] EP2SPKM — This bit masks the interrupt by EP2SPK flag. '0' : Disables '1' : Enables
    [4] EP2DRQM — This bit masks the interrupt by EP2DRQ flag. '0' : Disables '1' : Enables
    [3] EP1SPKM — This bit masks the interrupt by EP1SPK flag. '0' : Disables '1' : Enables
    [2] EP1DRQM — This bit masks the interrupt by EP1DRQ flag. '0' : Disables '1' : Enables
  0xA0C INTR_HOST_EP_MASKED ro — Interrupt USB Host Endpoint Masked Register
    [5] EP2SPKED — This bit indicates the interrupt by EP2SPK flag. '0' : Doesn't request the interrupt by EP2SPK '1' : Request the interrupt by EP2SPK
    [4] EP2DRQED — This bit indicates the interrupt by EP2DRQ flag. '0' : Doesn't request the interrupt by EP2DRQ '1' : Request the interrupt by EP2DRQ
    [3] EP1SPKED — This bit indicates the interrupt by EP1SPK flag. '0' : Doesn't request the interrupt by EP1SPK '1' : Request the interrupt by EP1SPK
    [2] EP1DRQED — This bit indicates the interrupt by EP1DRQ flag. '0' : Doesn't request the interrupt by EP1DRQ '1' : Request the interrupt by EP1DRQ
  0xB00 HOST_DMA_ENBL — Host DMA Enable Register
    [3] DM_EP2DRQE — This bit enables DMA Request by EP2DRQ. '0' : Disable '1' : Enable
    [2] DM_EP1DRQE — This bit enables DMA Request by EP1DRQ. '0' : Disable '1' : Enable
  0xB20 HOST_EP1_BLK — Host Endpoint 1 Block Register
    [31:16] BLK_NUM — Set the total byte number for DMA transfer. If HOST_EP1_RW1_DR or HOST_EP1_RW2_DR is written, the block number counter is decrement when DMAE='1'. - Set this bits before DMA transfer is enabled (HOST_DMA_ENBL.DM_DP1DRQE='1')
  0xB30 HOST_EP2_BLK — Host Endpoint 2 Block Register
    [31:16] BLK_NUM — Set the total byte number for DMA transfer. If HOST_EP2_RW1_DR or HOST_EP2_RW2_DR is written, the block number counter is decrement when DMAE='1'. - Set this bits before DMA transfer is enabled (HOST_DMA_ENBL.DM_DP2DRQE='1')
